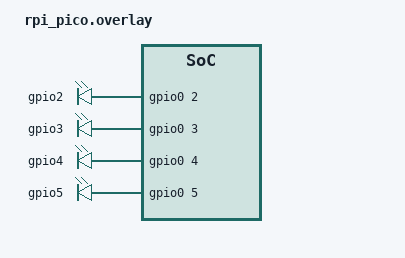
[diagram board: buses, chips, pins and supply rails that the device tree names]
/ {
    leds {
            compatible = "gpio-leds";
        
            gpio2: gpio_2 {
                gpios = <&gpio0 2 GPIO_ACTIVE_HIGH>;
                label = "gpio2";
            };
            gpio3: gpio_3 {
                gpios = <&gpio0 3 GPIO_ACTIVE_HIGH>;
                label = "gpio3";
            };
            gpio4: gpio_4 {
                gpios = <&gpio0 4 GPIO_ACTIVE_HIGH>;
                label = "gpio4";
            };
            gpio5: gpio_5 {
                gpios = <&gpio0 5 GPIO_ACTIVE_HIGH>;
                label = "gpio5";
            };
    };
    aliases {
		gpio2 = &gpio2;
        gpio3 = &gpio3;
        gpio4 = &gpio4;
        gpio5 = &gpio5;
	};
};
